# COMPUTE_CLUSTER0_ECC_AGGR_CFG register map
Vendor: Texas Instruments
Peripheral module from a debugger description file (folder J7ES).
Registers are 32-bit, access not given, reset 0x0 unless marked. A register's access mark holds for its fields unless they carry their own. Offsets are as the file gives them; lines under a group give offsets from that group; [hi:lo] are bit positions; {n}, {i} and the like mark numbered series; 'fields as' and 'values as' point back to an identical list; <NAME> marks a mode.

## COMPUTE_CLUSTER0_ECC_AGGR_CFG
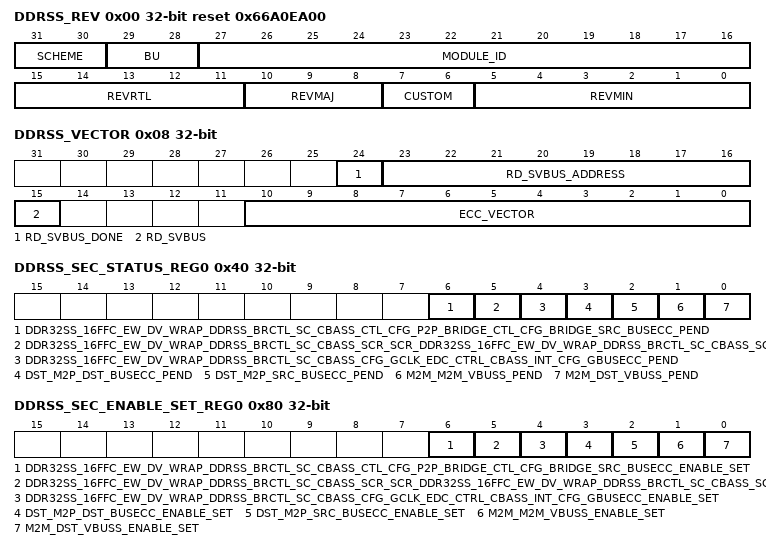
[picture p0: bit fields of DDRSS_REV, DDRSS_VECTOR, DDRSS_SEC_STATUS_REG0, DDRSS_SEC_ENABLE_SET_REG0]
0x00 DDRSS_REV ro reset 0x66A0EA00 — Revision parameters
  [31:30] SCHEME
  [29:28] BU
  [27:16] MODULE_ID
  [15:11] REVRTL — RTL version
  [10:8] REVMAJ — Major version
  [7:6] CUSTOM — Custom version
  [5:0] REVMIN — Minor version
0x08 DDRSS_VECTOR — ECC Vector Register
  [24] RD_SVBUS_DONE — Status to indicate if read on serial VBUS is complete, write of any value will clear this bit. (access RW1C)
  [23:16] RD_SVBUS_ADDRESS rw — Read address
  [15] RD_SVBUS — Write 1 to trigger a read on the serial VBUS (access RW1S)
  [10:0] ECC_VECTOR rw — Value written to select the corresponding ECC RAM for control or status
0x0C DDRSS_STAT ro reset 0x7 — Misc Status
  [10:0] NUM_RAMS — Indicates the number of RAMS serviced by the ECC aggregator
0x10 DDRSS_RESERVED_SVBUS_y rw — Reference other documents that contain the ECC RAM wrapper and EDC controller serial vbus register sets. Offset = 10h + (y * 4h); where y = 0h to 7h
  [31:0] DATA — Serial VBUS register data
0x3C DDRSS_SEC_EOI_REG — EOI Register The EOI register is used to re-trigger the pulse interrupt signal to ensure that any nested interrupt events are serviced. The software interrupt handler must write to the EOI register at the end of the current interrupt processing routine, so that new events can re-trigger the pulse interrupt signal again. For level interrupt signals the EOI register is not functional and must not be used.
  [0] EOI_WR — EOI Register (access RW1S)
0x40 DDRSS_SEC_STATUS_REG0 — Interrupt Status Register 0
  [6] DDR32SS_16FFC_EW_DV_WRAP_DDRSS_BRCTL_SC_CBASS_CTL_CFG_P2P_BRIDGE_CTL_CFG_BRIDGE_SRC_BUSECC_PEND — Interrupt Pending Status for ddr32ss_16ffc_ew_dv_wrap_ddrss_brctl_sc_cbass_ctl_cfg_p2p_bridge_ctl_cfg_bridge_src_busecc_pend (access RW1S)
  [5] DDR32SS_16FFC_EW_DV_WRAP_DDRSS_BRCTL_SC_CBASS_SCR_SCR_DDR32SS_16FFC_EW_DV_WRAP_DDRSS_BRCTL_SC_CBASS_SCR_SCR_EDC_CTRL_BUSECC_PEND — Interrupt Pending Status for ddr32ss_16ffc_ew_dv_wrap_ddrss_brctl_sc_cbass_scr_scr_ddr32ss_16ffc_ew_dv_wrap_ddrss_brctl_sc_cbass_scr_scr_edc_ctrl_busecc_pend (access RW1S)
  [4] DDR32SS_16FFC_EW_DV_WRAP_DDRSS_BRCTL_SC_CBASS_CFG_GCLK_EDC_CTRL_CBASS_INT_CFG_GBUSECC_PEND — Interrupt Pending Status for ddr32ss_16ffc_ew_dv_wrap_ddrss_brctl_sc_cbass_cfg_gclk_edc_ctrl_cbass_int_cfg_gbusecc_pend (access RW1S)
  [3] DST_M2P_DST_BUSECC_PEND — Interrupt Pending Status for dst_m2p_dst_busecc_pend (access RW1S)
  [2] DST_M2P_SRC_BUSECC_PEND — Interrupt Pending Status for dst_m2p_src_busecc_pend (access RW1S)
  [1] M2M_M2M_VBUSS_PEND — Interrupt Pending Status for m2m_m2m_vbuss_pend (access RW1S)
  [0] M2M_DST_VBUSS_PEND — Interrupt Pending Status for m2m_dst_vbuss_pend (access RW1S)
0x80 DDRSS_SEC_ENABLE_SET_REG0 — Interrupt Enable Set Register 0
  [6] DDR32SS_16FFC_EW_DV_WRAP_DDRSS_BRCTL_SC_CBASS_CTL_CFG_P2P_BRIDGE_CTL_CFG_BRIDGE_SRC_BUSECC_ENABLE_SET — Interrupt Enable Set Register for ddr32ss_16ffc_ew_dv_wrap_ddrss_brctl_sc_cbass_ctl_cfg_p2p_bridge_ctl_cfg_bridge_src_busecc_pend (access RW1S)
  [5] DDR32SS_16FFC_EW_DV_WRAP_DDRSS_BRCTL_SC_CBASS_SCR_SCR_DDR32SS_16FFC_EW_DV_WRAP_DDRSS_BRCTL_SC_CBASS_SCR_SCR_EDC_CTRL_BUSECC_ENABLE_SET — Interrupt Enable Set Register for ddr32ss_16ffc_ew_dv_wrap_ddrss_brctl_sc_cbass_scr_scr_ddr32ss_16ffc_ew_dv_wrap_ddrss_brctl_sc_cbass_scr_scr_edc_ctrl_busecc_pend (access RW1S)
  [4] DDR32SS_16FFC_EW_DV_WRAP_DDRSS_BRCTL_SC_CBASS_CFG_GCLK_EDC_CTRL_CBASS_INT_CFG_GBUSECC_ENABLE_SET — Interrupt Enable Set Register for ddr32ss_16ffc_ew_dv_wrap_ddrss_brctl_sc_cbass_cfg_gclk_edc_ctrl_cbass_int_cfg_gbusecc_pend (access RW1S)
  [3] DST_M2P_DST_BUSECC_ENABLE_SET — Interrupt Enable Set Register for dst_m2p_dst_busecc_pend (access RW1S)
  [2] DST_M2P_SRC_BUSECC_ENABLE_SET — Interrupt Enable Set Register for dst_m2p_src_busecc_pend (access RW1S)
  [1] M2M_M2M_VBUSS_ENABLE_SET — Interrupt Enable Set Register for m2m_m2m_vbuss_pend (access RW1S)
  [0] M2M_DST_VBUSS_ENABLE_SET — Interrupt Enable Set Register for m2m_dst_vbuss_pend (access RW1S)
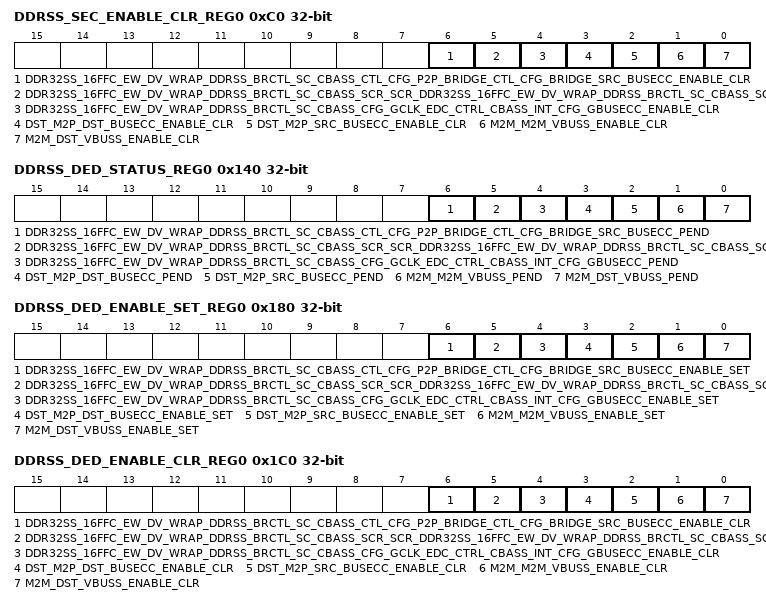
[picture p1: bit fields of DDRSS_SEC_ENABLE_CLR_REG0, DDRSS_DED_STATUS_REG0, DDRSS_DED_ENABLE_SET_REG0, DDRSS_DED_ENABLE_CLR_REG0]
0xC0 DDRSS_SEC_ENABLE_CLR_REG0 — Interrupt Enable Clear Register 0
  [6] DDR32SS_16FFC_EW_DV_WRAP_DDRSS_BRCTL_SC_CBASS_CTL_CFG_P2P_BRIDGE_CTL_CFG_BRIDGE_SRC_BUSECC_ENABLE_CLR — Interrupt Enable Clear Register for ddr32ss_16ffc_ew_dv_wrap_ddrss_brctl_sc_cbass_ctl_cfg_p2p_bridge_ctl_cfg_bridge_src_busecc_pend (access RW1C)
  [5] DDR32SS_16FFC_EW_DV_WRAP_DDRSS_BRCTL_SC_CBASS_SCR_SCR_DDR32SS_16FFC_EW_DV_WRAP_DDRSS_BRCTL_SC_CBASS_SCR_SCR_EDC_CTRL_BUSECC_ENABLE_CLR — Interrupt Enable Clear Register for ddr32ss_16ffc_ew_dv_wrap_ddrss_brctl_sc_cbass_scr_scr_ddr32ss_16ffc_ew_dv_wrap_ddrss_brctl_sc_cbass_scr_scr_edc_ctrl_busecc_pend (access RW1C)
  [4] DDR32SS_16FFC_EW_DV_WRAP_DDRSS_BRCTL_SC_CBASS_CFG_GCLK_EDC_CTRL_CBASS_INT_CFG_GBUSECC_ENABLE_CLR — Interrupt Enable Clear Register for ddr32ss_16ffc_ew_dv_wrap_ddrss_brctl_sc_cbass_cfg_gclk_edc_ctrl_cbass_int_cfg_gbusecc_pend (access RW1C)
  [3] DST_M2P_DST_BUSECC_ENABLE_CLR — Interrupt Enable Clear Register for dst_m2p_dst_busecc_pend (access RW1C)
  [2] DST_M2P_SRC_BUSECC_ENABLE_CLR — Interrupt Enable Clear Register for dst_m2p_src_busecc_pend (access RW1C)
  [1] M2M_M2M_VBUSS_ENABLE_CLR — Interrupt Enable Clear Register for m2m_m2m_vbuss_pend (access RW1C)
  [0] M2M_DST_VBUSS_ENABLE_CLR — Interrupt Enable Clear Register for m2m_dst_vbuss_pend (access RW1C)
0x13C DDRSS_DED_EOI_REG — EOI Register The EOI register is used to re-trigger the pulse interrupt signal to ensure that any nested interrupt events are serviced. The software interrupt handler must write to the EOI register at the end of the current interrupt processing routine, so that new events can re-trigger the pulse interrupt signal again. For level interrupt signals the EOI register is not functional and must not be used.
  [0] EOI_WR — EOI Register (access RW1S)
0x140 DDRSS_DED_STATUS_REG0 — Interrupt Status Register 0
  fields as DDRSS_SEC_STATUS_REG0
0x180 DDRSS_DED_ENABLE_SET_REG0 — Interrupt Enable Set Register 0
  fields as DDRSS_SEC_ENABLE_SET_REG0
0x1C0 DDRSS_DED_ENABLE_CLR_REG0 — Interrupt Enable Clear Register 0
  fields as DDRSS_SEC_ENABLE_CLR_REG0
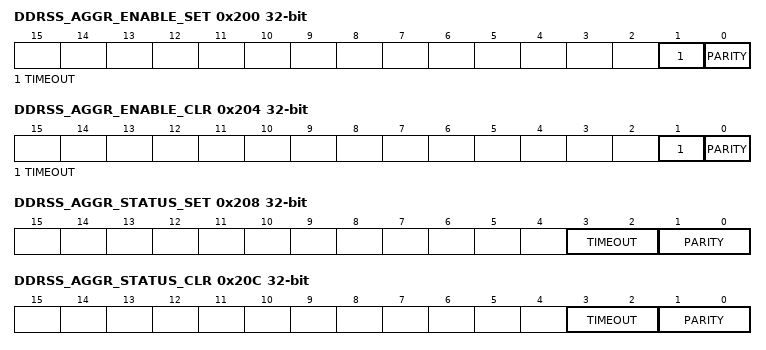
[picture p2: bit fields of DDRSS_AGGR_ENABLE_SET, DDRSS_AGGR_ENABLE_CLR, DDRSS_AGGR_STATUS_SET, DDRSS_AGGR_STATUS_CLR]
0x200 DDRSS_AGGR_ENABLE_SET — AGGR interrupt enable set Register
  [1] TIMEOUT — interrupt enable set for svbus timeout errors (access RW1S)
  [0] PARITY — interrupt enable set for parity errors (access RW1S)
0x204 DDRSS_AGGR_ENABLE_CLR — AGGR interrupt enable clear Register
  [1] TIMEOUT — interrupt enable clear for svbus timeout errors (access RW1C)
  [0] PARITY — interrupt enable clear for parity errors (access RW1C)
0x208 DDRSS_AGGR_STATUS_SET — AGGR interrupt status set Register
  [3:2] TIMEOUT — interrupt status set for svbus timeout errors (access RWincr)
  [1:0] PARITY — interrupt status set for parity errors (access RWincr)
0x20C DDRSS_AGGR_STATUS_CLR — AGGR interrupt status clear Register
  [3:2] TIMEOUT — interrupt status clear for svbus timeout errors (access RWdecr)
  [1:0] PARITY — interrupt status clear for parity errors (access RWdecr)
